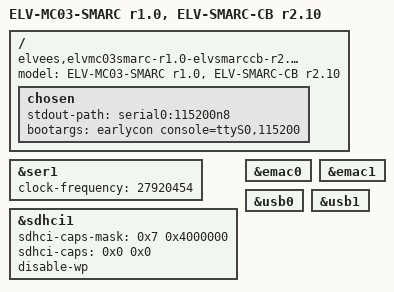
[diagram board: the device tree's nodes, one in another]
// SPDX-License-Identifier: GPL-2.0+
/*
 * Copyright 2023 RnD Center "ELVEES", JSC
 */

/dts-v1/;

#include <dt-bindings/gpio/gpio.h>

#include "mcom03-elvmc03smarc-r1.0.dtsi"

/ {	model = "ELV-MC03-SMARC r1.0, ELV-SMARC-CB r2.10";
	compatible = "elvees,elvmc03smarc-r1.0-elvsmarccb-r2.10",
		     "elvees,elvsmarccb-r2.10",
		     "elvees,elvsmarccb",
		     "elvees,elvmc03smarc-r1.0",
		     "elvees,elvmc03smarc",
		     "elvees,mcom03";

	chosen {
		stdout-path = "serial0:115200n8";
		bootargs = "earlycon console=ttyS0,115200";
	};
};

/* Connected to USB Type-C Debug UART */
&ser1 {
	status = "okay";
	clock-frequency = <27920454>;
};

&sdhci1 {
	status = "okay";

	/* Disable 1.8V support
	 * Disable SDR50, SDR104 and DDR50 support
	 */
	sdhci-caps-mask = <0x7 0x4000000>;
	sdhci-caps = <0x0 0x0>;

	/* SDIO_WP is not connected on ELV-SMARC-CB r2.10.3 */
	disable-wp;
};

&emac0 {
	status = "okay";
};

&emac1 {
	status = "okay";
};

&usb0 {
	status = "okay";
};

/* Connected to USB 2.0 hub */
&usb1 {
	status = "okay";
};
